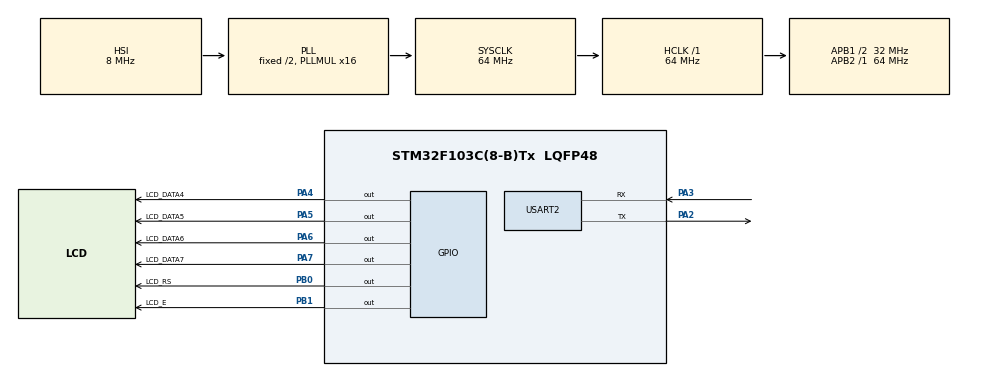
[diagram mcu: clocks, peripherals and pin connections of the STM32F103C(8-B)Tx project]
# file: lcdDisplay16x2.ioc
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Mcu.Family=STM32F1
Mcu.Name=STM32F103C(8-B)Tx
Mcu.Package=LQFP48
NVIC.PriorityGroup=NVIC_PRIORITYGROUP_4
PA13.Mode=Serial_Wire
PA13.Signal=SYS_JTMS-SWDIO
PA14.Mode=Serial_Wire
PA14.Signal=SYS_JTCK-SWCLK
PA2.Mode=Asynchronous
PA2.Signal=USART2_TX
PA3.Mode=Asynchronous
PA3.Signal=USART2_RX
PA4.GPIO_Label=LCD_DATA4
PA4.Signal=GPIO_Output
PA5.GPIO_Label=LCD_DATA5
PA5.Signal=GPIO_Output
PA6.GPIO_Label=LCD_DATA6
PA6.Signal=GPIO_Output
PA7.GPIO_Label=LCD_DATA7
PA7.Signal=GPIO_Output
PB0.GPIO_Label=LCD_RS
PB0.Signal=GPIO_Output
PB1.GPIO_Label=LCD_E
PB1.Signal=GPIO_Output
ProjectManager.HeapSize=0x200
ProjectManager.StackSize=0x400
ProjectManager.TargetToolchain=STM32CubeIDE
RCC.AHBFreq_Value=64000000
RCC.APB1CLKDivider=RCC_HCLK_DIV2
RCC.APB1Freq_Value=32000000
RCC.APB1TimFreq_Value=64000000
RCC.APB2Freq_Value=64000000
RCC.APB2TimFreq_Value=64000000
RCC.HCLKFreq_Value=64000000
RCC.PLLMUL=RCC_PLL_MUL16
RCC.SYSCLKFreq_VALUE=64000000
RCC.SYSCLKSource=RCC_SYSCLKSOURCE_PLLCLK
RCC.USBFreq_Value=64000000
TIM3.Prescaler=63
USART2.VirtualMode=VM_ASYNC
VP_TIM3_VS_ClockSourceINT.Mode=Internal
board=custom

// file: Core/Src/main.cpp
/* USER CODE BEGIN Header */
/**
  ******************************************************************************
  * @file           : main.c
  * @brief          : Main program body
  ******************************************************************************
  * @attention
  *
  * Copyright (c) 2022 STMicroelectronics.
  * All rights reserved.
  *
  * This software is licensed under terms that can be found in the LICENSE file
  * in the root directory of this software component.
  * If no LICENSE file comes with this software, it is provided AS-IS.
  *
  ******************************************************************************
  */
/* USER CODE END Header */
#include "main.h"
#include "tim.h"
#include "usart.h"
#include "gpio.h"

/* USER CODE BEGIN Includes */

#include "lcdDisplay/lcdDisplay.hpp"

/* USER CODE END Includes */

/* USER CODE BEGIN PV */

LcdDisplay display({Port::B, 0}, {Port::B, 1}, {Port::A, 4});

/* USER CODE END PV */

void SystemClock_Config(void);

int main(void)
{

  /* MCU Configuration--------------------------------------------------------*/

  /* Reset of all peripherals, Initializes the Flash interface and the Systick. */
  HAL_Init();

  /* Configure the system clock */
  SystemClock_Config();

  /* Initialize all configured peripherals */
  MX_GPIO_Init();
  MX_USART2_UART_Init();
  MX_TIM3_Init();
  /* USER CODE BEGIN 2 */

  HAL_TIM_Base_Start(&htim3);
  display.init();
  display.clear();

  //LCD_Init();

  /* USER CODE END 2 */

  /* Infinite loop */
  /* USER CODE BEGIN WHILE */
  while (1)
  {

	  display.clear();
	  display.setCursor(2, 1);
	  display.print('-');
	  display.print("lukasz ");
	  display.printInt(1234);
	  display.setCursor(0, 0);
	  display.print("lisnikowski");
	  HAL_Delay(1000);

    /* USER CODE END WHILE */

  }
}

void SystemClock_Config(void)
{
  RCC_OscInitTypeDef RCC_OscInitStruct = {0};
  RCC_ClkInitTypeDef RCC_ClkInitStruct = {0};

  /** Initializes the RCC Oscillators according to the specified parameters
  * in the RCC_OscInitTypeDef structure.
  */
  RCC_OscInitStruct.OscillatorType = RCC_OSCILLATORTYPE_HSI;
  RCC_OscInitStruct.HSIState = RCC_HSI_ON;
  RCC_OscInitStruct.HSICalibrationValue = RCC_HSICALIBRATION_DEFAULT;
  RCC_OscInitStruct.PLL.PLLState = RCC_PLL_ON;
  RCC_OscInitStruct.PLL.PLLSource = RCC_PLLSOURCE_HSI_DIV2;
  RCC_OscInitStruct.PLL.PLLMUL = RCC_PLL_MUL16;
  if (HAL_RCC_OscConfig(&RCC_OscInitStruct) != HAL_OK)
  {
    Error_Handler();
  }

  /** Initializes the CPU, AHB and APB buses clocks
  */
  RCC_ClkInitStruct.ClockType = RCC_CLOCKTYPE_HCLK|RCC_CLOCKTYPE_SYSCLK
                              |RCC_CLOCKTYPE_PCLK1|RCC_CLOCKTYPE_PCLK2;
  RCC_ClkInitStruct.SYSCLKSource = RCC_SYSCLKSOURCE_PLLCLK;
  RCC_ClkInitStruct.AHBCLKDivider = RCC_SYSCLK_DIV1;
  RCC_ClkInitStruct.APB1CLKDivider = RCC_HCLK_DIV2;
  RCC_ClkInitStruct.APB2CLKDivider = RCC_HCLK_DIV1;

  if (HAL_RCC_ClockConfig(&RCC_ClkInitStruct, FLASH_LATENCY_2) != HAL_OK)
  {
    Error_Handler();
  }
}

void Error_Handler(void)
{
  __disable_irq();
  while (1)
  {
  }
}
